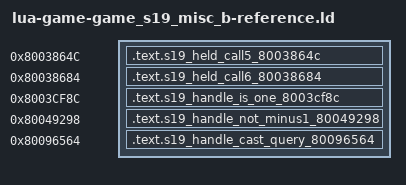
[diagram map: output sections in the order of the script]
/* Generated reference-only placements. All bodies are source-built. */
OUTPUT_FORMAT("elf32-powerpc")
OUTPUT_ARCH(powerpc)
ENTRY(s19_held_call5_8003864c)
_SDA_BASE_ = 0x804b2540;
_SDA2_BASE_ = 0x804c2540;
w3d_auto_80178c48 = 0x80178c48;
w3d_auto_80178d1c = 0x80178d1c;
w3d_constructor_native_cast = 0x80342a78;
SECTIONS {
  .text.s19_held_call5_8003864c 0x8003864c : { *(.text.s19_held_call5_8003864c) }
  .text.s19_held_call6_80038684 0x80038684 : { *(.text.s19_held_call6_80038684) }
  .text.s19_handle_is_one_8003cf8c 0x8003cf8c : { *(.text.s19_handle_is_one_8003cf8c) }
  .text.s19_handle_not_minus1_80049298 0x80049298 : { *(.text.s19_handle_not_minus1_80049298) }
  .text.s19_handle_cast_query_80096564 0x80096564 : { *(.text.s19_handle_cast_query_80096564) }
  /DISCARD/ : { *(.text*) *(.rodata*) *(.data*) *(.bss*) *(.sdata*) *(.sbss*) *(.comment) }
}
